# ADuCM363 register map
Vendor: Analog Devices Inc.; Series: ADuCM36x; File version: 0.1
CPU: CM3 r2p1, little endian, no MPU, no FPU, 3 interrupt priority bits
Registers are 16-bit, read-write, no defined reset value unless marked. A register's access mark holds for its fields unless they carry their own. Offsets are from the block's base; [hi:lo] are bit positions; 'fields as' and 'values as' point back to an identical list.

## ADI_DMA — Direct Memory Access
Base 0x40010000
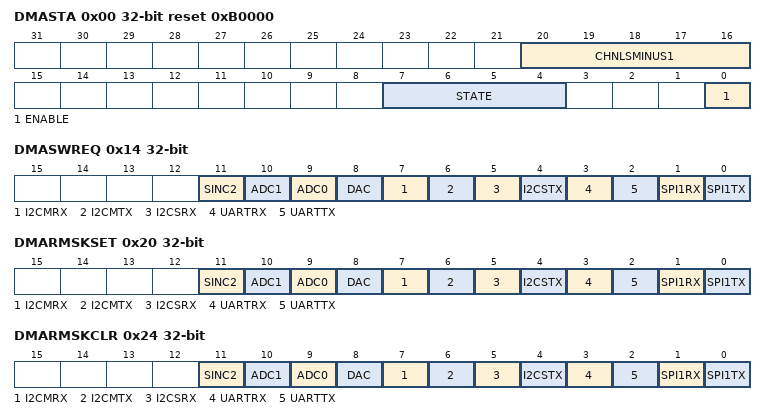
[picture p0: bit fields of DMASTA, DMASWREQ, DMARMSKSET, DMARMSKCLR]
0x00 DMASTA 32-bit ro reset 0xB0000 (reset mask 0x0) — Returns the status of the controller when not in the reset state.
  [20:16] CHNLSMINUS1 — Number of available DMA channels minus one.
    13=FOURTEENCHNLS (- Controller configured to use 14 DMA channels); 11=TWELVECHNLS (- Controller configured to use 12 DMA channels)
  [7:4] STATE — Current state of the control state machine.
    0=IDLE; 1=RDCHNLDATA (- Reading channel controller data); 2=RDSRCENDPTR (- Reading source data end pointer); 3=RDDSTENDPTR (- Reading destination data end pointer); 4=RDSRCDATA (- Reading source data); 5=WRDSTDATA (- Writing destination data); 6=WAITDMAREQCLR (- Waiting for DMA request to clear); 7=WRCHNLDATA (- Writing channel controller data); 8=STALLED; 9=DONE; 10=SCATRGATHR (- Peripheral scatter-gather transition)
  [0] ENABLE — Master DMA controller enable status.
    0=CLR; 1=SET
0x04 DMACFG 32-bit — Configuraton
  [0] ENABLE — Master DMA controller enable
    0=DIS; 1=EN
0x08 DMAPDBPTR 32-bit — Channel primary control database pointer
  [31:0] CTRLBASEPTR range 0x00000000..0xFFFFFFFF — Pointer to the base address of the primary data structure
0x0C DMAADBPTR 32-bit ro reset 0x100 (reset mask 0x0) — Channel alt control database pointer
  [31:0] ALTCBPTR range 0x00000000..0xFFFFFFFF — Pointer to the base address of the alternate data structure
0x14 DMASWREQ 32-bit wo — Channel Software Request
  [all] fields
    0=DIS; 1=EN
  [11] SINC2 — SINC2 Output Step detection
  [10] ADC1
  [9] ADC0
  [8] DAC — DAC DMA Output
  [7] I2CMRX — DMA I2C Master RX
  [6] I2CMTX — DMA I2C Master TX
  [5] I2CSRX — DMA I2C Slave RX
  [4] I2CSTX — DMA I2C Slave TX
  [3] UARTRX — DMA UART RX
  [2] UARTTX — DMA UART TX
  [1] SPI1RX — DMA SPI 1 RX
  [0] SPI1TX — DMA SPI 1 TX
0x20 DMARMSKSET 32-bit — Channel Request Mask Set
  fields as DMASWREQ
0x24 DMARMSKCLR 32-bit wo — Channel Request Mask Clear
  fields as DMASWREQ
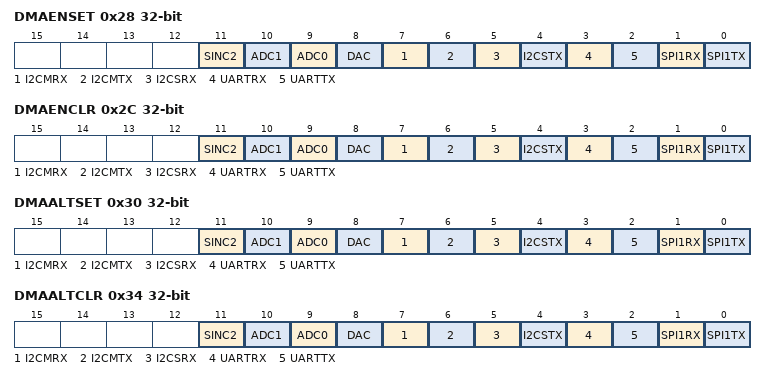
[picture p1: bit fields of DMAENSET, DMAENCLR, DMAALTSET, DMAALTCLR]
0x28 DMAENSET 32-bit — Channel Enable Set
  fields as DMASWREQ
0x2C DMAENCLR 32-bit wo — Channel Enable Clear
  fields as DMASWREQ
0x30 DMAALTSET 32-bit — Channel Primary-Alternate Set
  fields as DMASWREQ
0x34 DMAALTCLR 32-bit wo — Channel Primary-Alternate Clear
  fields as DMASWREQ
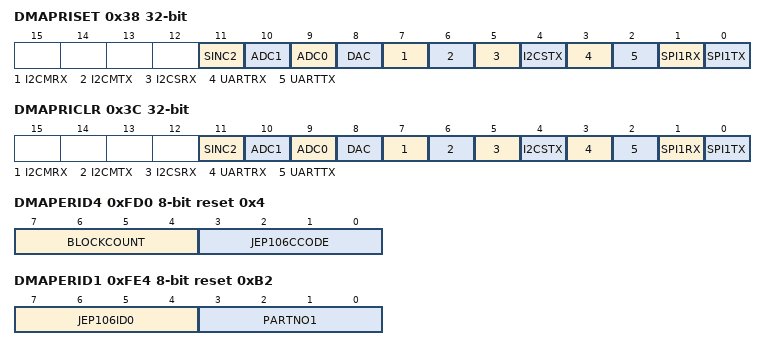
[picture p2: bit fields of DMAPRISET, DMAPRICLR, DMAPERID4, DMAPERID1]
0x38 DMAPRISET 32-bit — Channel Priority Set
  fields as DMASWREQ
0x3C DMAPRICLR 32-bit wo — Channel Priority Clear
  fields as DMASWREQ
0x4C DMAERRCLR 32-bit — Bus Error Clear
  [0] ERROR — DMA Error status
    0=DIS; 1=EN
0xFD0 DMAPERID4 8-bit ro reset 0x4 (reset mask 0x0) — Peripheral identification 4
  [7:4] BLOCKCOUNT range 0x00000000..0x0000000F — The number of 4KB address blocks you require, to access the registers, expressed in powers of 2.
  [3:0] JEP106CCODE range 0x00000000..0x0000000F — The JEP106 continuation code value represents how many 0x7F continuation characters occur in the manufacturer?s identity code.
0xFE0 DMAPERID0 8-bit ro reset 0x30 (reset mask 0x0) — Peripheral identification 0
  [7:0] PARTNO0 range 0x00000000..0x000000FF — Identifies the peripheral (part_number_0)
0xFE4 DMAPERID1 8-bit ro reset 0xB2 (reset mask 0x0) — Peripheral identification 1
  [7:4] JEP106ID0 range 0x00000000..0x0000000F — JEP106 identity code [3:0]
  [3:0] PARTNO1 range 0x00000000..0x0000000F — Identifies the peripheral (part_number_1)
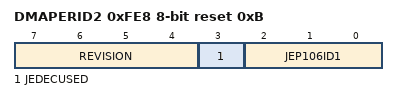
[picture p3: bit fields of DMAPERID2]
0xFE8 DMAPERID2 8-bit ro reset 0xB (reset mask 0x0) — Peripheral identification 2
  [7:4] REVISION range 0x00000000..0x0000000F — The revision status of the controller.
  [3] JEDECUSED — This indicates that the controller uses a manufacturer?s identity code that was allocated by JEDEC according to JEP106.
    0=DIS; 1=EN
  [2:0] JEP106ID1 range 0x00000000..0x00000007 — JEP106 identity code [6:4].
0xFEC DMAPERID3 8-bit ro — Peripheral identification 3
  [3:0] MODNUM range 0x00000000..0x0000000F — The customer must update this field if they modify the RTL of the controller.
0xFF0 DMAPCELLID0 8-bit ro reset 0xD (reset mask 0x0) — PrimeCell identification 0
  [7:0] PCELLID0 range 0x00000000..0x000000FF — Primecell Identification
0xFF4 DMAPCELLID1 8-bit ro reset 0xF0 (reset mask 0x0) — PrimeCell identification 1
  [7:0] PCELLID1 range 0x00000000..0x000000FF — Primecell Identification
0xFF8 DMAPCELLID2 8-bit ro reset 0x5 (reset mask 0x0) — PrimeCell identification 2
  [7:0] PCELLID2 range 0x00000000..0x000000FF — Primecell Identification
0xFFC DMAPCELLID3 8-bit ro reset 0xB1 (reset mask 0x0) — PrimeCell identification 3
  [7:0] PCELLID3 range 0x00000000..0x000000FF — Primecell Identification
